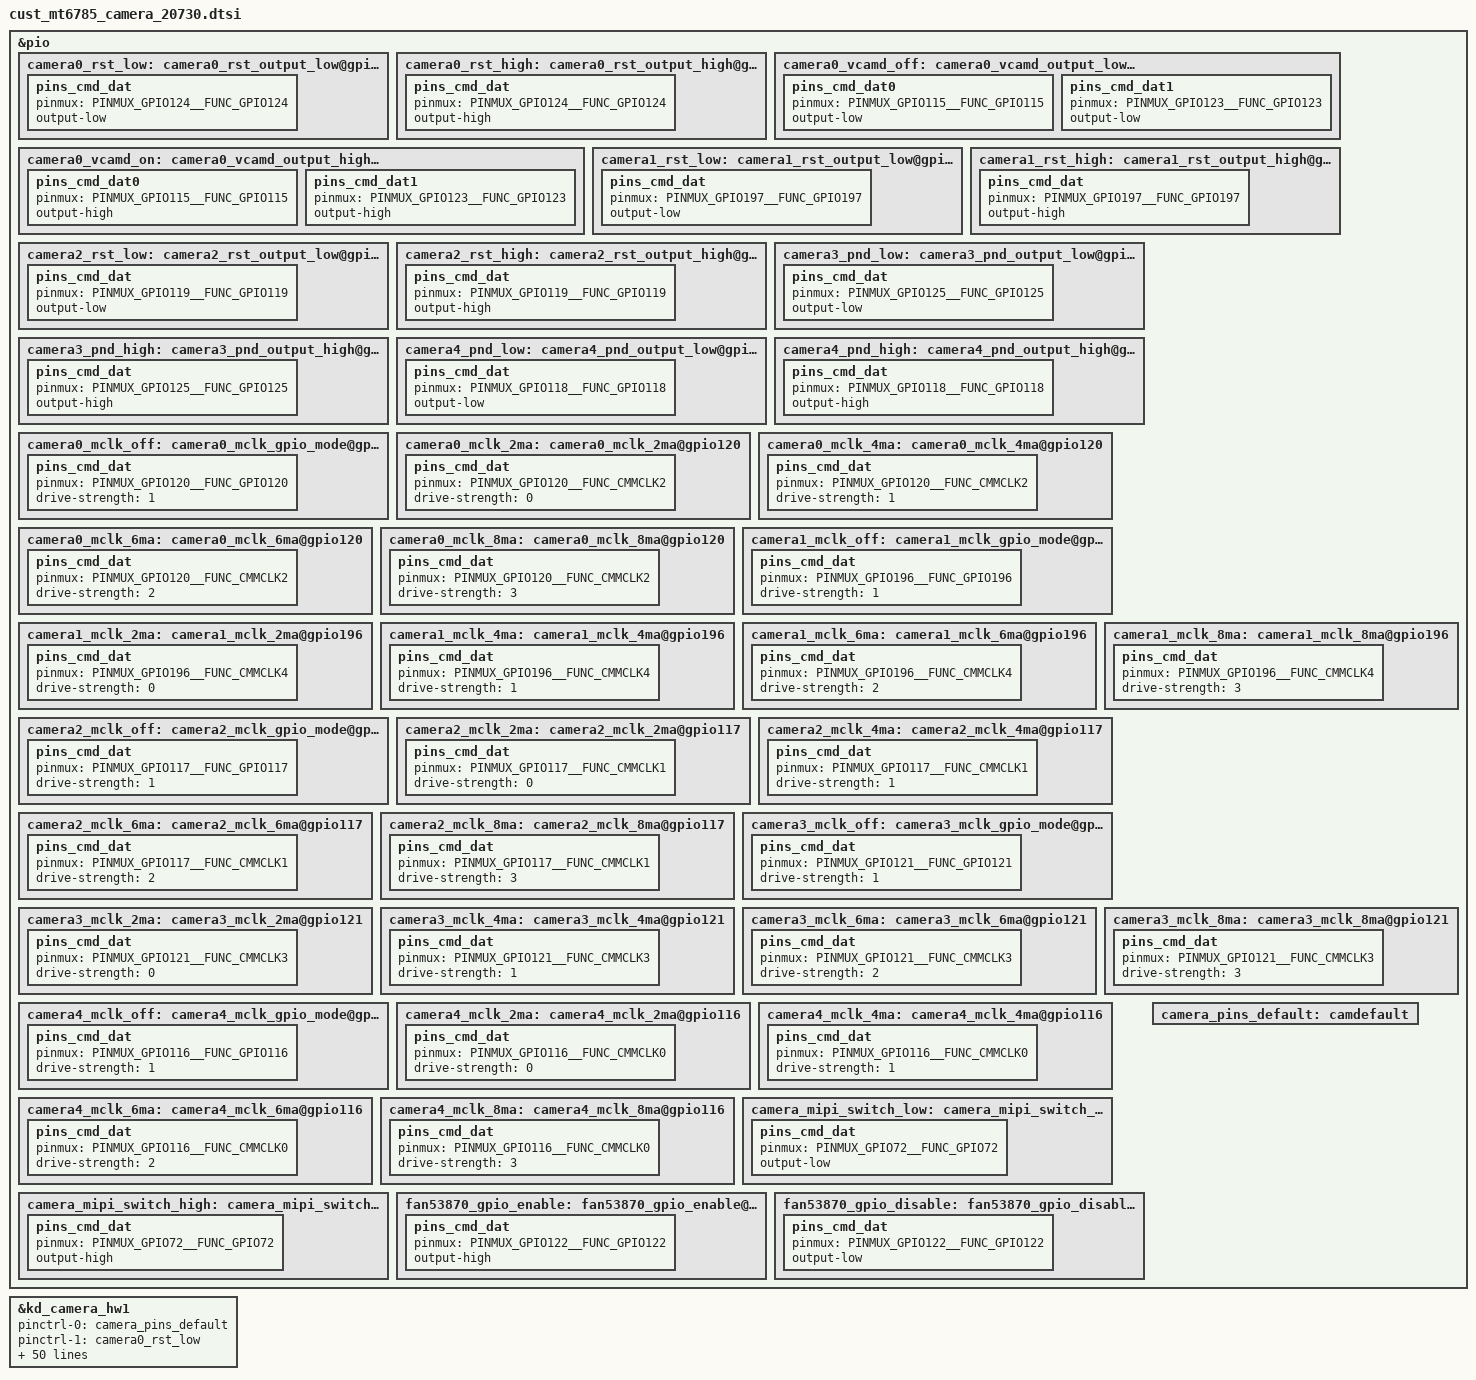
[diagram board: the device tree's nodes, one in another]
/*
 * Copyright (c) 2017 MediaTek Inc.
 *
 * This program is free software; you can redistribute it and/or modify
 * it under the terms of the GNU General Public License version 2 as
 * published by the Free Software Foundation.
 *
 * This program is distributed in the hope that it will be useful,
 * but WITHOUT ANY WARRANTY; without even the implied warranty of
 * MERCHANTABILITY or FITNESS FOR A PARTICULAR PURPOSE.  See the
 * GNU General Public License for more details.
 */
/* CAMERA GPIO standardization */
&pio {
	camera0_rst_low: camera0_rst_output_low@gpio124 {
		pins_cmd_dat {
			pinmux = <PINMUX_GPIO124__FUNC_GPIO124>;
			output-low;
		};
	};
	camera0_rst_high: camera0_rst_output_high@gpio124 {
		pins_cmd_dat {
			pinmux = <PINMUX_GPIO124__FUNC_GPIO124>;
			output-high;
		};
	};
	camera0_vcamd_off: camera0_vcamd_output_low@gpio123 {
		pins_cmd_dat0 {
			pinmux = <PINMUX_GPIO115__FUNC_GPIO115>;
			output-low;
		};
		pins_cmd_dat1 {
			pinmux = <PINMUX_GPIO123__FUNC_GPIO123>;
			output-low;
		};
	};
	camera0_vcamd_on: camera0_vcamd_output_high@gpio123 {
		pins_cmd_dat0 {
			pinmux = <PINMUX_GPIO115__FUNC_GPIO115>;
			output-high;
		};
		pins_cmd_dat1 {
			pinmux = <PINMUX_GPIO123__FUNC_GPIO123>;
			output-high;
		};
	};
	camera1_rst_low: camera1_rst_output_low@gpio197 {
		pins_cmd_dat {
			pinmux = <PINMUX_GPIO197__FUNC_GPIO197>;
			output-low;
		};
	};
	camera1_rst_high: camera1_rst_output_high@gpio197 {
		pins_cmd_dat {
			pinmux = <PINMUX_GPIO197__FUNC_GPIO197>;
			output-high;
		};
	};
	camera2_rst_low: camera2_rst_output_low@gpio119 {
		pins_cmd_dat {
			pinmux = <PINMUX_GPIO119__FUNC_GPIO119>;
			output-low;
		};
	};
	camera2_rst_high: camera2_rst_output_high@gpio119 {
		pins_cmd_dat {
			pinmux = <PINMUX_GPIO119__FUNC_GPIO119>;
			output-high;
		};
	};
	camera3_pnd_low: camera3_pnd_output_low@gpio125 {
		pins_cmd_dat {
			pinmux = <PINMUX_GPIO125__FUNC_GPIO125>;
			output-low;
		};
	};
	camera3_pnd_high: camera3_pnd_output_high@gpio125 {
		pins_cmd_dat {
			pinmux = <PINMUX_GPIO125__FUNC_GPIO125>;
			output-high;
		};
	};
	camera4_pnd_low: camera4_pnd_output_low@gpio118 {
		pins_cmd_dat {
			pinmux = <PINMUX_GPIO118__FUNC_GPIO118>;
			output-low;
		};
	};
	camera4_pnd_high: camera4_pnd_output_high@gpio118 {
		pins_cmd_dat {
			pinmux = <PINMUX_GPIO118__FUNC_GPIO118>;
			output-high;
		};
	};
	camera0_mclk_off: camera0_mclk_gpio_mode@gpio120 {
		pins_cmd_dat {
			pinmux = <PINMUX_GPIO120__FUNC_GPIO120>;
			drive-strength = <1>;
		};
	};
	camera0_mclk_2ma: camera0_mclk_2ma@gpio120 {
		pins_cmd_dat {
			pinmux = <PINMUX_GPIO120__FUNC_CMMCLK2>;
			drive-strength = <0>;
		};
	};
	camera0_mclk_4ma: camera0_mclk_4ma@gpio120 {
		pins_cmd_dat {
			pinmux = <PINMUX_GPIO120__FUNC_CMMCLK2>;
			drive-strength = <1>;
		};
	};
	camera0_mclk_6ma: camera0_mclk_6ma@gpio120 {
		pins_cmd_dat {
			pinmux = <PINMUX_GPIO120__FUNC_CMMCLK2>;
			drive-strength = <2>;
		};
	};
	camera0_mclk_8ma: camera0_mclk_8ma@gpio120 {
		pins_cmd_dat {
			pinmux = <PINMUX_GPIO120__FUNC_CMMCLK2>;
			drive-strength = <3>;
		};
	};
	camera1_mclk_off: camera1_mclk_gpio_mode@gpio196 {
		pins_cmd_dat {
			pinmux = <PINMUX_GPIO196__FUNC_GPIO196>;
			drive-strength = <1>;
		};
	};
	camera1_mclk_2ma: camera1_mclk_2ma@gpio196 {
		pins_cmd_dat {
			pinmux = <PINMUX_GPIO196__FUNC_CMMCLK4>;
			drive-strength = <0>;
		};
	};
	camera1_mclk_4ma: camera1_mclk_4ma@gpio196 {
		pins_cmd_dat {
			pinmux = <PINMUX_GPIO196__FUNC_CMMCLK4>;
			drive-strength = <1>;
		};
	};
	camera1_mclk_6ma: camera1_mclk_6ma@gpio196 {
		pins_cmd_dat {
			pinmux = <PINMUX_GPIO196__FUNC_CMMCLK4>;
			drive-strength = <2>;
		};
	};
	camera1_mclk_8ma: camera1_mclk_8ma@gpio196 {
		pins_cmd_dat {
			pinmux = <PINMUX_GPIO196__FUNC_CMMCLK4>;
			drive-strength = <3>;
		};
	};
	camera2_mclk_off: camera2_mclk_gpio_mode@gpio117 {
		pins_cmd_dat {
			pinmux = <PINMUX_GPIO117__FUNC_GPIO117>;
			drive-strength = <1>;
		};
	};
	camera2_mclk_2ma: camera2_mclk_2ma@gpio117 {
		pins_cmd_dat {
			pinmux = <PINMUX_GPIO117__FUNC_CMMCLK1>;
			drive-strength = <0>;
		};
	};
	camera2_mclk_4ma: camera2_mclk_4ma@gpio117 {
		pins_cmd_dat {
			pinmux = <PINMUX_GPIO117__FUNC_CMMCLK1>;
			drive-strength = <1>;
		};
	};
	camera2_mclk_6ma: camera2_mclk_6ma@gpio117 {
		pins_cmd_dat {
			pinmux = <PINMUX_GPIO117__FUNC_CMMCLK1>;
			drive-strength = <2>;
		};
	};
	camera2_mclk_8ma: camera2_mclk_8ma@gpio117 {
		pins_cmd_dat {
			pinmux = <PINMUX_GPIO117__FUNC_CMMCLK1>;
			drive-strength = <3>;
		};
	};
	camera3_mclk_off: camera3_mclk_gpio_mode@gpio121 {
		pins_cmd_dat {
			pinmux = <PINMUX_GPIO121__FUNC_GPIO121>;
			drive-strength = <1>;
		};
	};
	camera3_mclk_2ma: camera3_mclk_2ma@gpio121 {
		pins_cmd_dat {
			pinmux = <PINMUX_GPIO121__FUNC_CMMCLK3>;
			drive-strength = <0>;
		};
	};
	camera3_mclk_4ma: camera3_mclk_4ma@gpio121 {
		pins_cmd_dat {
			pinmux = <PINMUX_GPIO121__FUNC_CMMCLK3>;
			drive-strength = <1>;
		};
	};
	camera3_mclk_6ma: camera3_mclk_6ma@gpio121 {
		pins_cmd_dat {
			pinmux = <PINMUX_GPIO121__FUNC_CMMCLK3>;
			drive-strength = <2>;
		};
	};
	camera3_mclk_8ma: camera3_mclk_8ma@gpio121 {
		pins_cmd_dat {
			pinmux = <PINMUX_GPIO121__FUNC_CMMCLK3>;
			drive-strength = <3>;
		};
	};
	camera4_mclk_off: camera4_mclk_gpio_mode@gpio116 {
		pins_cmd_dat {
			pinmux = <PINMUX_GPIO116__FUNC_GPIO116>;
			drive-strength = <1>;
		};
	};
	camera4_mclk_2ma: camera4_mclk_2ma@gpio116 {
		pins_cmd_dat {
			pinmux = <PINMUX_GPIO116__FUNC_CMMCLK0>;
			drive-strength = <0>;
		};
	};
	camera4_mclk_4ma: camera4_mclk_4ma@gpio116 {
		pins_cmd_dat {
			pinmux = <PINMUX_GPIO116__FUNC_CMMCLK0>;
			drive-strength = <1>;
		};
	};
	camera4_mclk_6ma: camera4_mclk_6ma@gpio116 {
		pins_cmd_dat {
			pinmux = <PINMUX_GPIO116__FUNC_CMMCLK0>;
			drive-strength = <2>;
		};
	};
	camera4_mclk_8ma: camera4_mclk_8ma@gpio116 {
		pins_cmd_dat {
			pinmux = <PINMUX_GPIO116__FUNC_CMMCLK0>;
			drive-strength = <3>;
		};
	};
	camera_mipi_switch_low: camera_mipi_switch_low@gpio72 {
		pins_cmd_dat {
			pinmux = <PINMUX_GPIO72__FUNC_GPIO72>;
			output-low;
		};
	};
	camera_mipi_switch_high: camera_mipi_switch_high@gpio72 {
		pins_cmd_dat {
			pinmux = <PINMUX_GPIO72__FUNC_GPIO72>;
			output-high;
		};
	};
	fan53870_gpio_enable: fan53870_gpio_enable@gpio122 {
			pins_cmd_dat {
			pinmux = <PINMUX_GPIO122__FUNC_GPIO122>;
			output-high;
		};
	};
	fan53870_gpio_disable: fan53870_gpio_disable@gpi122 {
			pins_cmd_dat {
			pinmux = <PINMUX_GPIO122__FUNC_GPIO122>;
			output-low;
		};
	};
	camera_pins_default: camdefault {
	};
};
&kd_camera_hw1 {
	pinctrl-names = "default",
			"cam0_rst0", "cam0_rst1",
			"cam0_ldo_vcamd_0", "cam0_ldo_vcamd_1",
			"cam1_rst0", "cam1_rst1",
			"cam2_rst0", "cam2_rst1",
			"cam3_pnd0", "cam3_pnd1",
			"cam4_pnd0", "cam4_pnd1",
			"cam0_mclk_off",
			"cam0_mclk_2mA", "cam0_mclk_4mA",
			"cam0_mclk_6mA", "cam0_mclk_8mA",
			"cam1_mclk_off",
			"cam1_mclk_2mA", "cam1_mclk_4mA",
			"cam1_mclk_6mA", "cam1_mclk_8mA",
			"cam2_mclk_off",
			"cam2_mclk_2mA", "cam2_mclk_4mA",
			"cam2_mclk_6mA", "cam2_mclk_8mA",
			"cam3_mclk_off",
			"cam3_mclk_2mA", "cam3_mclk_4mA",
			"cam3_mclk_6mA", "cam3_mclk_8mA",
			"cam4_mclk_off",
			"cam4_mclk_2mA", "cam4_mclk_4mA",
			"cam4_mclk_6mA", "cam4_mclk_8mA",
			"cam_mipi_switch_sel_0", "cam_mipi_switch_sel_1",
			"fan53870_chip_enable",	"fan53870_chip_disable";
	pinctrl-0 = <&camera_pins_default>;
	pinctrl-1 = <&camera0_rst_low>;
	pinctrl-2 = <&camera0_rst_high>;
	pinctrl-3 = <&camera0_vcamd_off>;
	pinctrl-4 = <&camera0_vcamd_on>;
	pinctrl-5 = <&camera1_rst_low>;
	pinctrl-6 = <&camera1_rst_high>;
	pinctrl-7 = <&camera2_rst_low>;
	pinctrl-8 = <&camera2_rst_high>;
	pinctrl-9 = <&camera3_pnd_low>;
	pinctrl-10 = <&camera3_pnd_high>;
	pinctrl-11 = <&camera4_pnd_low>;
	pinctrl-12 = <&camera4_pnd_high>;
	pinctrl-13 = <&camera0_mclk_off>;
	pinctrl-14 = <&camera0_mclk_2ma>;
	pinctrl-15 = <&camera0_mclk_4ma>;
	pinctrl-16 = <&camera0_mclk_6ma>;
	pinctrl-17 = <&camera0_mclk_8ma>;
	pinctrl-18 = <&camera1_mclk_off>;
	pinctrl-19 = <&camera1_mclk_2ma>;
	pinctrl-20 = <&camera1_mclk_4ma>;
	pinctrl-21 = <&camera1_mclk_6ma>;
	pinctrl-22 = <&camera1_mclk_8ma>;
	pinctrl-23 = <&camera2_mclk_off>;
	pinctrl-24 = <&camera2_mclk_2ma>;
	pinctrl-25 = <&camera2_mclk_4ma>;
	pinctrl-26 = <&camera2_mclk_6ma>;
	pinctrl-27 = <&camera2_mclk_8ma>;
	pinctrl-28 = <&camera3_mclk_off>;
	pinctrl-29 = <&camera3_mclk_2ma>;
	pinctrl-30 = <&camera3_mclk_4ma>;
	pinctrl-31 = <&camera3_mclk_6ma>;
	pinctrl-32 = <&camera3_mclk_8ma>;
	pinctrl-33 = <&camera4_mclk_off>;
	pinctrl-34 = <&camera4_mclk_2ma>;
	pinctrl-35 = <&camera4_mclk_4ma>;
	pinctrl-36 = <&camera4_mclk_6ma>;
	pinctrl-37 = <&camera4_mclk_8ma>;
	pinctrl-38 = <&camera_mipi_switch_low>;
	pinctrl-39 = <&camera_mipi_switch_high>;
	pinctrl-40 = <&fan53870_gpio_enable>;
	pinctrl-41 = <&fan53870_gpio_disable>;


	cam0_vcamio-supply = <&mt_pmic_vcamio_ldo_reg>;
	cam1_vcamio-supply = <&mt_pmic_vcamio_ldo_reg>;
	cam2_vcamio-supply = <&mt_pmic_vcamio_ldo_reg>;
	cam3_vcamio-supply = <&mt_pmic_vcamio_ldo_reg>;
	cam4_vcamio-supply = <&mt_pmic_vcamio_ldo_reg>;

	cam0_enable_sensor = "ov64b_mipi_raw_20730";
	cam1_enable_sensor = "imx471_mipi_raw2_20730";
	cam2_enable_sensor = "ov8856_mipi_raw2_20730";
	cam3_enable_sensor = "gc02m1_mipi_raw_20730";
	cam4_enable_sensor = "gc02m1b_mipi_mono_20730";

	status = "okay";
};
/* CAMERA GPIO  end */
